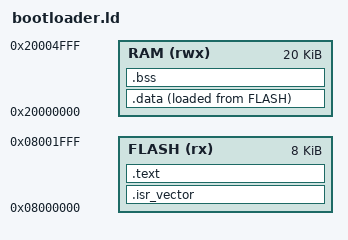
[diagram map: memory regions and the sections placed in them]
/*
 * bootloader.ld - STM32F1（128KB Flash）A/B OTA Bootloader 链接脚本
 *
 * FLASH 仅用前 8KB（0x08000000..0x08001FFF），A 区从 0x08002000 开始。
 * RAM 20KB，主栈直接从 SRAM 顶端向下增长（Bootloader 不使用堆）。
 */

ENTRY(Reset_Handler)

MEMORY
{
    FLASH (rx)  : ORIGIN = 0x08000000, LENGTH = 8K
    RAM   (rwx) : ORIGIN = 0x20000000, LENGTH = 20K
}

_estack = ORIGIN(RAM) + LENGTH(RAM);

SECTIONS
{
    .isr_vector :
    {
        . = ALIGN(4);
        KEEP(*(.isr_vector))
        . = ALIGN(4);
    } > FLASH

    .text :
    {
        . = ALIGN(4);
        *(.text .text.*)
        *(.rodata .rodata.*)
        *(.glue_7 .glue_7t)
        *(.eh_frame)
        . = ALIGN(4);
        _etext = .;
    } > FLASH

    .data :
    {
        . = ALIGN(4);
        _sdata = .;
        *(.data .data.*)
        . = ALIGN(4);
        _edata = .;
    } > RAM AT > FLASH
    _sidata = LOADADDR(.data);

    .bss (NOLOAD) :
    {
        . = ALIGN(4);
        _sbss = .;
        *(.bss .bss.*)
        *(COMMON)
        . = ALIGN(4);
        _ebss = .;
    } > RAM

    /DISCARD/ :
    {
        *(.ARM.exidx*)
        *(.ARM.extab*)
        *(.note*)
        *(.comment*)
    }

    .ARM.attributes 0 : { *(.ARM.attributes) }
}
